# thuasrv32 register map
Vendor: jesseopdenbrouw; Series: RISC-V; File version: 0.2.1
The THUAS RV32 RISC-V Processor
CPU: THUASRV32 r2p1, little endian, no MPU, no FPU, 4 interrupt priority bits
Registers are 32-bit, read-write, no defined reset value unless marked. A register's access mark holds for its fields unless they carry their own. Offsets are from the block's base; lines under a group give offsets from that group; [hi:lo] are bit positions; {n}, {i} and the like mark numbered series; 'fields as' and 'values as' point back to an identical list; <NAME> marks a mode.

## Memory map
0xF0000000 GPIO size 0x10 — General purpose input/output port
0xF0000100 UART1 size 0x10 — Universal Asynchronous Receiver/Transmitter
0xF0000200 I2C1 size 0xC — Inter-Integrated Circuit 1
0xF0000300 I2C2 size 0xC — Inter-Integrated Circuit 2
0xF0000400 SPI1 size 0xC — Serial Peripheral interface 1
0xF0000500 SPI2 size 0xC — Serial Peripheral interface 2
0xF0000600 TIMER1 size 0x10
0xF0000700 TIMER2 size 0x20
0xF0000800 WDT size 0x8 — Watchdog Timer
0xF0000900 MSI size 0x4 — Machine Software Interrupt
0xF0000A00 MTIME size 0x10 — Machine timer
0xF0000B00 UART2 size 0x10 — Universal Asynchronous Receiver/Transmitter

## Interrupts
3 MSI_IRQ (MSI)
7 MTIME_IRQ (MTIME)
18 EXTI_IRQ (GPIO)
19 UART1_BR_IRQ (UART2)
19 UART1_RX_IRQ (UART2)
19 UART1_TX_IRQ (UART2)
20 TIMER1_CMPT_IRQ (TIMER1)
21 TIMER2_CMPT_IRQ (TIMER2)
23 UART1_BR_IRQ (UART1)
23 UART1_RX_IRQ (UART1)
23 UART1_TX_IRQ (UART1)
24 I2C2_TC_IRQ (I2C2)
25 SPI2_TC_IRQ (SPI2)
26 I2C1_TC_IRQ (I2C1)
27 SPI1_TC_IRQ (SPI1)
31 WDT_IRQ (WDT)

## MTIME — Machine timer
Base 0xF0000A00
0x00 MTIME — System time register - low
0x04 MTIMEH — System time register - high
0x08 MTIMECMP — Time compare register - low
0x0C MTIMECMPH — Time compare register - high

## GPIO — General purpose input/output port
Base 0xF0000000
0x00 PIN ro — Parallel input register
0x04 POUT — Parallel output register
0x08 PSET wo — Bit set register
0x0C PCLR wo — Bit clear register
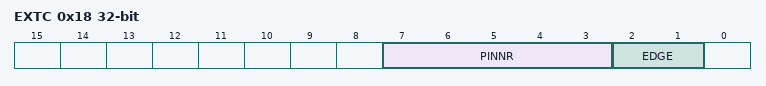
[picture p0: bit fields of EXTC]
0x18 EXTC — External input interrupt control register
  [7:3] PINNR — GPIO Pin input Select
  [2:1] EDGE — Select Edge
0x1C EXTS — External input interrupt status register
  [0] DETECT — Edge detected

## UART1 — Universal Asynchronous Receiver/Transmitter
Base 0xF0000100
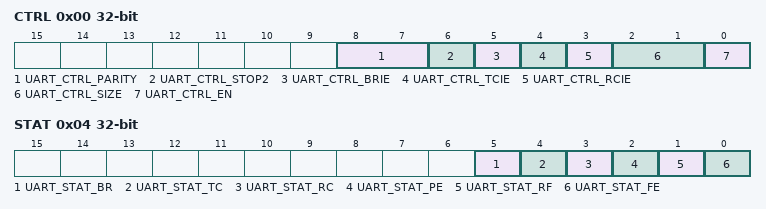
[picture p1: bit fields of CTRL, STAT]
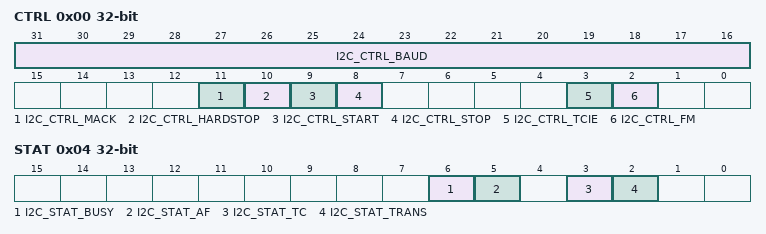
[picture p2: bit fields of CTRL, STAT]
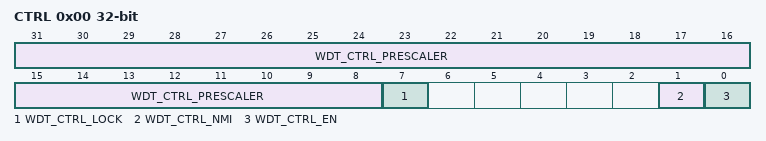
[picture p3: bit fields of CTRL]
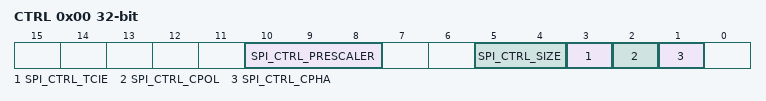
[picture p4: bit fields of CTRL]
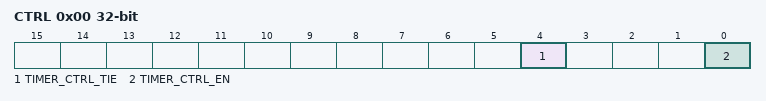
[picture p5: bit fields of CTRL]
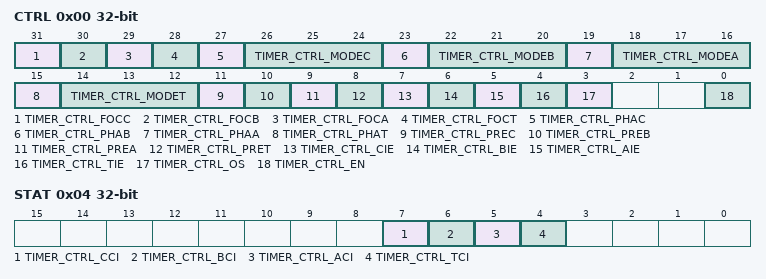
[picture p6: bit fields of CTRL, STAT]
0x00 CTRL — Control register
  [8:7] UART_CTRL_PARITY — Parity
  [6] UART_CTRL_STOP2 — Two STOP bits enable
  [5] UART_CTRL_BRIE — Break Received interrupt enable
  [4] UART_CTRL_TCIE — Transmit Complete interrupt enable
  [3] UART_CTRL_RCIE — Receive Complete interrupt enable
  [2:1] UART_CTRL_SIZE — Data size in frame
  [0] UART_CTRL_EN — UART enable flag
0x04 STAT — Status register
  [5] UART_STAT_BR — BREAK Detected
  [4] UART_STAT_TC — Transmit Complete
  [3] UART_STAT_RC — Receive Complete
  [2] UART_STAT_PE — Parity Error
  [1] UART_STAT_RF — Receive Failed
  [0] UART_STAT_FE — Frame Error
0x08 DATA
  [9:0] DATA — Data to transmit or receive
0x0C BAUD — Baud rate divisor register
  [15:0] PRESCALER — Baud rate prescaler

## I2C1 — Inter-Integrated Circuit 1
Base 0xF0000200
Same registers: I2C2 0xF0000300
0x00 CTRL — Control register
  [31:16] I2C_CTRL_BAUD — I2C Baudrate Fiels
  [11] I2C_CTRL_MACK — I2C Master Acknowlegde enable
  [10] I2C_CTRL_HARDSTOP — I2C Transmit direct STOP condition
  [9] I2C_CTRL_START — I2C Transmit START condition
  [8] I2C_CTRL_STOP — I2C Transmit STOP condition
  [3] I2C_CTRL_TCIE — I2C Transmit Complete Interrupt Enable
  [2] I2C_CTRL_FM — I2C Fast Mode select
0x04 STAT — Status register
  [6] I2C_STAT_BUSY — I2C Bus Busy
  [5] I2C_STAT_AF — I2C Acknowledge Failed
  [3] I2C_STAT_TC — I2C Tramission Complete
  [2] I2C_STAT_TRANS — I2C Tramission in progress
0x08 DATA
  [7:0] I2C_DATA

## WDT — Watchdog Timer
Base 0xF0000800
0x00 CTRL — Control register
  [31:8] WDT_CTRL_PRESCALER — Watchdog Prescaler
  [7] WDT_CTRL_LOCK — Watchdog Lock Enable
  [1] WDT_CTRL_NMI — Watchdog NMI Enable
  [0] WDT_CTRL_EN — Watchdog Enable
0x04 TRIG wo — Trigger register
  [31:0] WDT_TRIG_PASSWORD — Password field

## MSI — Machine Software Interrupt
Base 0xF0000900
0x00 TRIG — Trigger register
  [0] MSI_TRIG — MSI Trigger field

## SPI1 — Serial Peripheral interface 1
Base 0xF0000400
Same registers: SPI2 0xF0000500
0x00 CTRL — Control register
  [10:8] SPI_CTRL_PRESCALER — SPI Prescaler
  [5:4] SPI_CTRL_SIZE — SPI Transmission Size
  [3] SPI_CTRL_TCIE — SPI Transmission Complete Interrupt Enable
  [2] SPI_CTRL_CPOL — SPI Clock Polarity
  [1] SPI_CTRL_CPHA — SPI Clock Phase
0x04 STAT — Status register
  [3] SPI_STAT_TC — SPI Transmission Complete
0x08 DATA
  [31:0] SPI_DATA_DATA — SPI Data Field

## TIMER1
Base 0xF0000600
0x00 CTRL — Control register
  [4] TIMER_CTRL_TIE — Timer 1 Compare Match Interrupt Enable
  [0] TIMER_CTRL_EN — Timer 1 Enable
0x04 STAT — Status register
  [4] TIMER_STAT_TCI — Timer 1 Compare Match Interrupt
0x08 CNTR — Counter register
0x0C CMPT — Compare Match T register

## TIMER2
Base 0xF0000700
0x00 CTRL — Control register
  [31] TIMER_CTRL_FOCC — Timer 2 Force Compare Match C
  [30] TIMER_CTRL_FOCB — Timer 2 Force Compare Match B
  [29] TIMER_CTRL_FOCA — Timer 2 Force Compare Match A
  [28] TIMER_CTRL_FOCT — Timer 2 Force Compare Match T
  [27] TIMER_CTRL_PHAC — Timer 2 C Phase
  [26:24] TIMER_CTRL_MODEC — Timer 2 C Mode Field
  [23] TIMER_CTRL_PHAB — Timer 2 B Phase
  [22:20] TIMER_CTRL_MODEB — Timer 2 B Mode Field
  [19] TIMER_CTRL_PHAA — Timer 2 A Phase
  [18:16] TIMER_CTRL_MODEA — Timer 2 A Mode Field
  [15] TIMER_CTRL_PHAT — Timer 2 T Phase
  [14:12] TIMER_CTRL_MODET — Timer 2 T Mode Field
  [11] TIMER_CTRL_PREC — Timer 2 Preload C Enable
  [10] TIMER_CTRL_PREB — Timer 2 Preload B Enable
  [9] TIMER_CTRL_PREA — Timer 2 Preload A Enable
  [8] TIMER_CTRL_PRET — Timer 2 Preload T Enable
  [7] TIMER_CTRL_CIE — Timer 2 Compare Match C Interrupt Enable
  [6] TIMER_CTRL_BIE — Timer 2 Compare Match B Interrupt Enable
  [5] TIMER_CTRL_AIE — Timer 2 Compare Match A Interrupt Enable
  [4] TIMER_CTRL_TIE — Timer 2 Compare Match T Interrupt Enable
  [3] TIMER_CTRL_OS — Timer 2 One Shot
  [0] TIMER_CTRL_EN — Timer 2 Enable
0x04 STAT — Status register
  [7] TIMER_CTRL_CCI — Timer 2 Compare Match C Interrupt
  [6] TIMER_CTRL_BCI — Timer 2 Compare Match B Interrupt
  [5] TIMER_CTRL_ACI — Timer 2 Compare Match A Interrupt
  [4] TIMER_CTRL_TCI — Timer 2 Compare Match T Interrupt
0x08 CNTR — Counter register
  [15:0] TIMER_CNTR_CNTR — Timer 2 Counter Register
0x0C CMPT — Compare Match T Register
  [15:0] TIMER_CMPT_CMPT — Timer 2 Compare Match T Register
0x10 PSRC — Prescaler Register
  [15:0] TIMER_PRSC_PRSC — Timer 2 Prescaler Register
0x14 CMPA — Compare Match A Register
  [15:0] TIMER_CMPA_CMPA — Timer 2 Compare Match A Register
0x18 CMPB — Compare Match B Register
  [15:0] TIMER_CMPB_CMPB — Timer 2 Compare Match B Register
0x1C CMPC — Compare Match C Register
  [15:0] TIMER_CMPC_CMPC — Timer 2 Compare Match C Register
